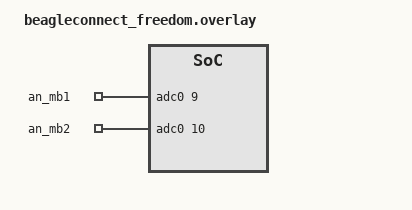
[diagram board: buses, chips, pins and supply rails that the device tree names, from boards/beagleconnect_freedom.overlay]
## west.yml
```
# Copyright (c) 2024 Jason Kridner <jkridner@beagleboard.org>
# SPDX-License-Identifier: Apache-2.0

manifest:
  self:
    west-commands: scripts/west-commands.yml

  remotes:
    - name: upstream
      url-base: https://github.com/zephyrproject-rtos
    - name: jadonk
      url-base: https://github.com/jadonk

  projects:
    - name: zephyr-1
      remote: jadonk
      path: zephyr
      revision: pm-fixes
      import:
        name-allowlist:
          - hal_ti
          - cmsis_6
          - cmsis-dsp
          - mcuboot
          - mbedtls
          - zcbor
```

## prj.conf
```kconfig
CONFIG_ASSERT=y

# Devices
CONFIG_LED=y
CONFIG_GPIO=y
CONFIG_SENSOR=y
CONFIG_ADC=y
CONFIG_SERIAL=y

# Networking
CONFIG_IEEE802154=y
CONFIG_IEEE802154_NET_IF_NO_AUTO_START=y
CONFIG_IEEE802154_CC13XX_CC26XX=n
CONFIG_IEEE802154_CC13XX_CC26XX_SUB_GHZ=y
CONFIG_IEEE802154_CC13XX_CC26XX_SUB_GHZ_NUM_RX_BUF=6
CONFIG_NETWORKING=y
CONFIG_NET_IF_UNICAST_IPV6_ADDR_COUNT=3
CONFIG_NET_IF_MCAST_IPV6_ADDR_COUNT=4
CONFIG_NET_MAX_CONN=8
CONFIG_NET_MAX_CONTEXTS=10
CONFIG_NET_CONTEXT_NET_PKT_POOL=y
CONFIG_NET_PKT_RX_COUNT=8
CONFIG_NET_BUF_RX_COUNT=64
CONFIG_NET_PKT_TX_COUNT=20
CONFIG_NET_BUF_TX_COUNT=50
CONFIG_NET_STATISTICS=y
CONFIG_NET_SOCKETS=y
CONFIG_POSIX_API=y
CONFIG_NET_SOCKETS_POLL_MAX=8
CONFIG_NET_L2_IEEE802154=y
CONFIG_NET_MGMT=y
CONFIG_NET_MGMT_EVENT=y

# Misc
CONFIG_MAIN_STACK_SIZE=8192
#CONFIG_SHELL_STACK_SIZE=12188
CONFIG_ENTROPY_GENERATOR=y
CONFIG_NET_MGMT_EVENT_STACK_SIZE=1024
CONFIG_PM=y
CONFIG_PM_DEVICE=y
CONFIG_PM_DEVICE_RUNTIME=y
#CONFIG_PM_DEVICE_SYSTEM_MANAGED=y
CONFIG_IDLE_STACK_SIZE=1024
CONFIG_SYSTEM_WORKQUEUE_STACK_SIZE=2048

# Logging
CONFIG_LOG=y
CONFIG_LOG_PRINTK=y
CONFIG_LOG_BACKEND_UART=y
CONFIG_LOG_MODE_IMMEDIATE=y
CONFIG_NET_LOG=y
CONFIG_NET_CONFIG_LOG_LEVEL_DBG=y
CONFIG_NET_SOCKETS_LOG_LEVEL_DBG=y
CONFIG_NET_L2_IEEE802154_LOG_LEVEL_DBG=y
CONFIG_IEEE802154_DRIVER_LOG_LEVEL_DBG=y
CONFIG_PM_LOG_LEVEL_DBG=y
CONFIG_PM_DEVICE_LOG_LEVEL_DBG=y
#CONFIG_UART_LOG_LEVEL_DBG=y
#CONFIG_MPU_LOG_LEVEL_DBG=y
#CONFIG_SOC_LOG_LEVEL_DBG=y
#CONFIG_I2C_LOG_LEVEL_DBG=y
#CONFIG_ADC_LOG_LEVEL_DBG=y
#CONFIG_SENSOR_LOG_LEVEL_DBG=y
#CONFIG_KERNEL_LOG_LEVEL_DBG=y

CONFIG_REBOOT=y
CONFIG_REQUIRES_FULL_LIBC=y

# Adjust for oscillator capacitors
CONFIG_CC13X2_CC26X2_XOSC_CAPARRAY_DELTA=0x02
```

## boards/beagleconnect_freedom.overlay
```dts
/*
 * Copyright (c) 2025, Jason Kridner, BeagleBoard.org Foundation
 *
 * SPDX-License-Identifier: Apache-2.0
 */

/ {
	zephyr,user {
		io-channels = <&adc0 9>, <&adc0 10>;
		io-channel-names = "an_mb1", "an_mb2";
	};
};
```

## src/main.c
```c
/*
 * Copyright (c) 2025 Jason Kridner, BeagleBoard.org Foundation
 *
 * Sourced from ChatGPT
 *
 * SPDX-License-Identifier: Apache-2.0
 */

#include <cmsis_core.h>
#include <zephyr/device.h>
#include <zephyr/devicetree.h>
#include <zephyr/drivers/adc.h>
#include <zephyr/irq.h>
#include <zephyr/kernel.h>
#include <zephyr/logging/log.h>
#include <ti/devices/DeviceFamily.h>
#include DeviceFamily_constructPath(inc/hw_aux_evctl.h)
#include DeviceFamily_constructPath(inc/hw_aux_anaif.h)
#include DeviceFamily_constructPath(inc/hw_memmap.h)
#include DeviceFamily_constructPath(inc/hw_types.h)

LOG_MODULE_REGISTER(adc_repro, LOG_LEVEL_INF);

#define SAMPLES 256

/* Match BeagleConnect Freedom overlay names */
static const struct device *const adc = DEVICE_DT_GET(DT_NODELABEL(adc0));
static const struct adc_dt_spec an_mb1_dt =
    ADC_DT_SPEC_GET_BY_NAME(DT_PATH(zephyr_user), an_mb1);
static const struct adc_dt_spec an_mb2_dt =
    ADC_DT_SPEC_GET_BY_NAME(DT_PATH(zephyr_user), an_mb2);

#define ADC_NODE DT_NODELABEL(adc0)
#define ADC_IRQ DT_IRQN(ADC_NODE)

static void dump_irq_state(const char *tag) {
  uint32_t primask = __get_PRIMASK();
  uint32_t basepri = __get_BASEPRI();
  uint32_t idx = ADC_IRQ / 32;
  uint32_t bit = BIT(ADC_IRQ % 32);
  uint32_t iser = NVIC->ISER[idx];
  uint32_t ispr = NVIC->ISPR[idx];

  LOG_DBG("[%s] PRIMASK=%u BASEPRI=0x%02x", tag, primask, basepri);
  LOG_DBG("[%s] NVIC->ISER[%u]=0x%08x ISPR[%u]=0x%08x", tag, idx, iser, idx,
          ispr);
  LOG_DBG("[%s] ADC IRQ %d enabled=%d pending=%d", tag, ADC_IRQ,
          irq_is_enabled(ADC_IRQ), (ispr & bit) ? 1 : 0);
}

static void dump_aux_adc_flags(const char *tag) {
  uint32_t evflags = HWREG(AUX_EVCTL_BASE + AUX_EVCTL_O_EVTOMCUFLAGS);
  uint32_t adcctl = HWREG(AUX_ANAIF_BASE + AUX_ANAIF_O_ADCCTL);

  LOG_DBG("[%s] AUX_EVCTL.EVTOMCUFLAGS = 0x%08x", tag, evflags);
  LOG_DBG("[%s] AUX_ANAIF.ADCCTL       = 0x%08x", tag, adcctl);
}

int main(void) {
  int r;
  uint16_t mb1_buf;
  uint16_t mb2_buf;

  struct adc_sequence mb1_seq = {
      .buffer = &mb1_buf,
      .buffer_size = sizeof(mb1_buf),
  };
  struct adc_sequence mb2_seq = {
      .buffer = &mb2_buf,
      .buffer_size = sizeof(mb2_buf),
  };

  LOG_INF("BeagleConnect Freedom ADC repro main()");

  if (!device_is_ready(adc)) {
    LOG_ERR("ADC device not ready");
    return -1;
  }

  while (1) {
    LOG_INF("Sleeping 1s before measurement");
    k_sleep(K_SECONDS(1));

    /* --- AN_MB1 read --- */
    LOG_DBG("Calling adc_channel_setup_dt(an_mb1)");
    r = adc_channel_setup_dt(&an_mb1_dt);
    if(r != 0) LOG_ERR("adc_channel_setup_dt(an_mb1) rc=%d", r);

    LOG_DBG("Calling adc_sequence_init_dt(an_mb1)");
    r = adc_sequence_init_dt(&an_mb1_dt, &mb1_seq);
    if(r != 0) LOG_ERR("adc_sequence_init_dt(an_mb1) rc=%d", r);

    LOG_DBG("Calling adc_read_dt(an_mb1)");
    dump_irq_state("an_mb1");
    dump_aux_adc_flags("an_mb1");
    r = adc_read_dt(&an_mb1_dt, &mb1_seq);
    if(r != 0) LOG_ERR("adc_read_dt(an_mb1) rc=%d", r);

    if (r == 0) {
      LOG_INF("AN_MB1 raw: %u", mb1_buf);
    }

    //return 0;

    /* --- AN_MB2 read: 256 samples --- */
    LOG_DBG("AN_MB2 read, %d samples", SAMPLES);

    for (size_t j = 0; j < SAMPLES; j++) {
      LOG_DBG("Calling adc_channel_setup_dt(an_mb2) (%u)", (unsigned)j);
      r = adc_channel_setup_dt(&an_mb2_dt);
      if (r < 0) {
        LOG_ERR("adc_channel_setup_dt(an_mb2) rc=%d", r);
        break;
      }

      LOG_DBG("Calling adc_sequence_init_dt(an_mb2)");
      r = adc_sequence_init_dt(&an_mb2_dt, &mb2_seq);
      if (r != 0) {
        LOG_ERR("adc_sequence_init_dt(an_mb2) failed: %d", r);
        break;
      }

      dump_irq_state("an_mb2");
      LOG_DBG("Calling adc_read_dt(an_mb2)");
      r = adc_read_dt(&an_mb2_dt, &mb2_seq);
      if (r != 0) {
        LOG_ERR("adc_read_dt(an_mb2) (%u) failed: %d", (unsigned)j, r);
      } else {
        LOG_DBG("AN_MB2 raw: %u", mb2_buf);
      }
      /* Uncomment if you want ~1 kHz sampling spacing */
      // k_sleep(K_MSEC(1));
    }
    if (r == 0) {
      LOG_INF("AN_MB2 last raw: %u", mb2_buf);
    }
  }

  return 0;
}
```
